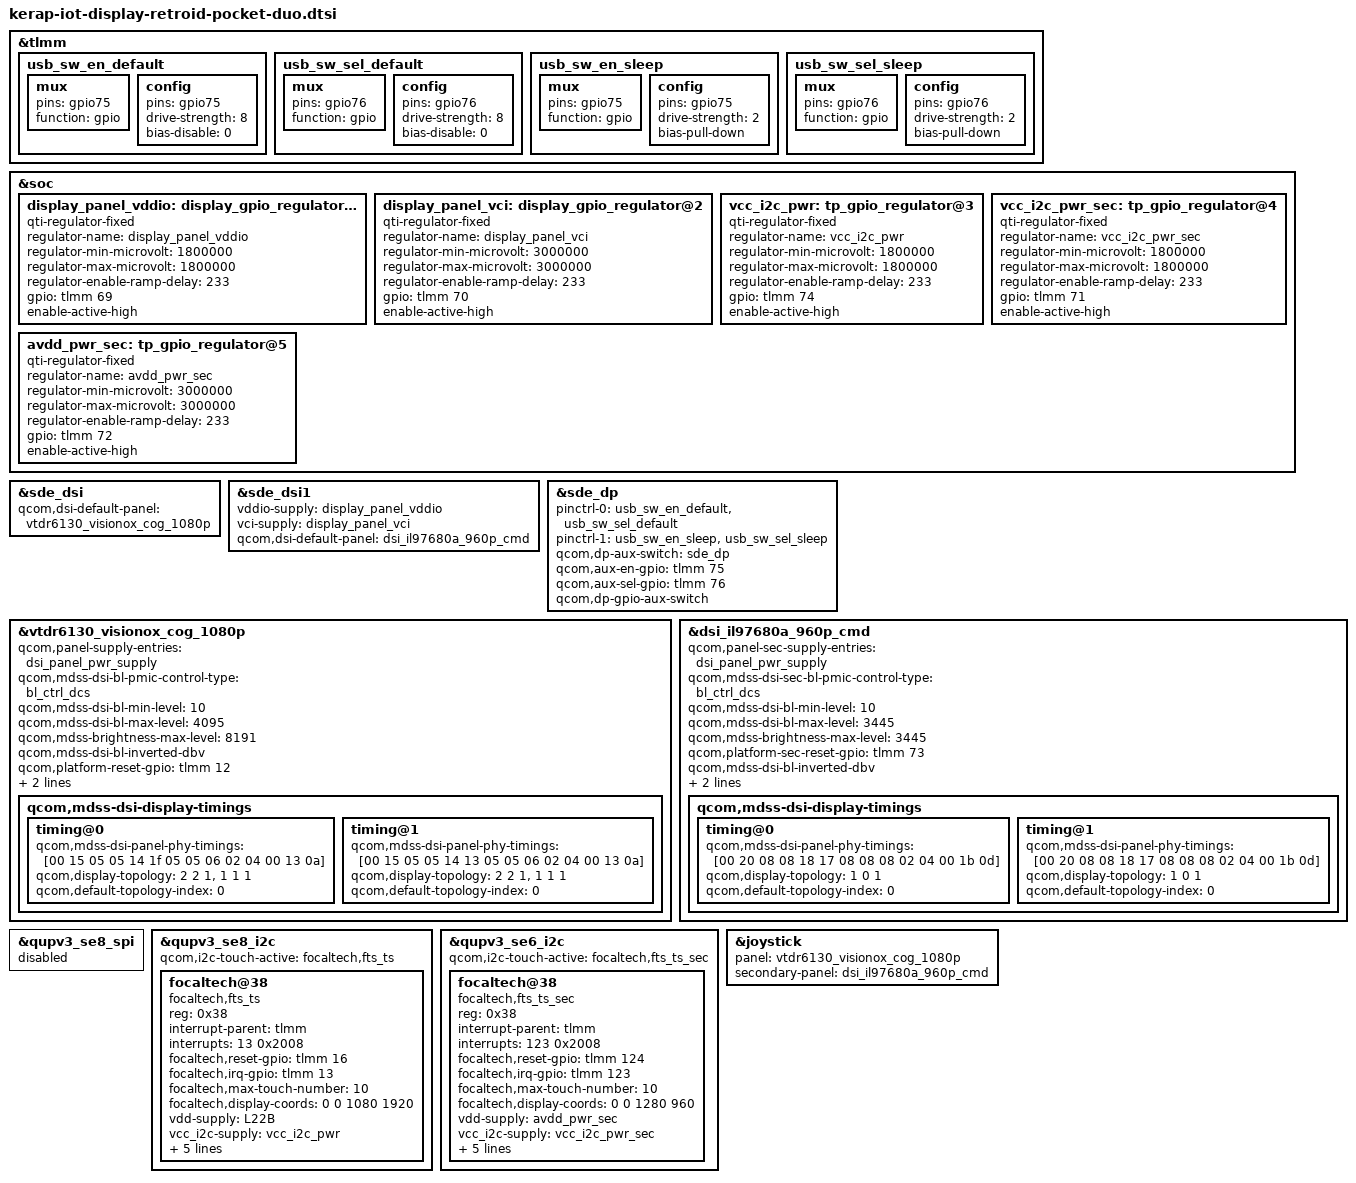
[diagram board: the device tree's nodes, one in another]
#include "../../../qcom/display/display/kera-sde.dtsi"
#include "../../../qcom/display/display/kera-sde-display-mtp.dtsi"

#include "panels/dsi-panel-il97680a-xing-960p-120hz-cmd.dtsi"
#include "panels/dsi-panel-vtdr6130-visionox-cog-1080p-cmd.dtsi"

&tlmm {
	usb_sw_en_default: usb_sw_en_default {
		mux {
			pins = "gpio75";
			function = "gpio";
		};

		config {
			pins = "gpio75";
			drive-strength = <8>;
			bias-disable = <0>;
		};
	};

	usb_sw_sel_default: usb_sw_sel_default {
		mux {
			pins = "gpio76";
			function = "gpio";
		};

		config {
			pins = "gpio76";
			drive-strength = <8>;
			bias-disable = <0>;
		};
	};

	usb_sw_en_sleep: usb_sw_en_sleep {
		mux {
			pins = "gpio75";
			function = "gpio";
		};

		config {
			pins = "gpio75";
			drive-strength = <2>;
			bias-pull-down;
		};
	};

	usb_sw_sel_sleep: usb_sw_sel_sleep {
		mux {
			pins = "gpio76";
			function = "gpio";
		};

		config {
			pins = "gpio76";
			drive-strength = <2>;
			bias-pull-down;
		};
	};
};

&soc {
	display_panel_vddio: display_gpio_regulator@1 {
		compatible = "qti-regulator-fixed";
		regulator-name = "display_panel_vddio";
		regulator-min-microvolt = <1800000>;
		regulator-max-microvolt = <1800000>;
		regulator-enable-ramp-delay = <233>;
		gpio = <&tlmm 69 0>;
		enable-active-high;
		pinctrl-names = "default";
	};

	display_panel_vci: display_gpio_regulator@2 {
		compatible = "qti-regulator-fixed";
		regulator-name = "display_panel_vci";
		regulator-min-microvolt = <3000000>;
		regulator-max-microvolt = <3000000>;
		regulator-enable-ramp-delay = <233>;
		gpio = <&tlmm 70 0>;
		enable-active-high;
		pinctrl-names = "default";
	};

	vcc_i2c_pwr: tp_gpio_regulator@3 {
		compatible = "qti-regulator-fixed";
		regulator-name = "vcc_i2c_pwr";
		regulator-min-microvolt = <1800000>;
		regulator-max-microvolt = <1800000>;
		regulator-enable-ramp-delay = <233>;
		gpio = <&tlmm 74 0>;
		enable-active-high;
		pinctrl-names = "default";
	};

	vcc_i2c_pwr_sec: tp_gpio_regulator@4 {
		compatible = "qti-regulator-fixed";
		regulator-name = "vcc_i2c_pwr_sec";
		regulator-min-microvolt = <1800000>;
		regulator-max-microvolt = <1800000>;
		regulator-enable-ramp-delay = <233>;
		gpio = <&tlmm 71 0>;
		enable-active-high;
		pinctrl-names = "default";
	};

	avdd_pwr_sec: tp_gpio_regulator@5 {
		compatible = "qti-regulator-fixed";
		regulator-name = "avdd_pwr_sec";
		regulator-min-microvolt = <3000000>;
		regulator-max-microvolt = <3000000>;
		regulator-enable-ramp-delay = <233>;
		gpio = <&tlmm 72 0>;
		enable-active-high;
		pinctrl-names = "default";
	};
};

&sde_dsi {
	qcom,dsi-default-panel = <&vtdr6130_visionox_cog_1080p>;
	status = "okay";
};

&sde_dsi1 {
	/delete-property/ vddio-supply;
	/delete-property/ vci-supply;
	vddio-supply = <&display_panel_vddio>;
	vci-supply = <&display_panel_vci>;
	qcom,dsi-default-panel = <&dsi_il97680a_960p_cmd>;
	status = "okay";
};

&sde_dp {
	pinctrl-names = "mdss_dp_active", "mdss_dp_sleep";
	pinctrl-0 = <&usb_sw_en_default &usb_sw_sel_default>;
	pinctrl-1 = <&usb_sw_en_sleep &usb_sw_sel_sleep>;
	qcom,dp-aux-switch = <&sde_dp>;
	qcom,aux-en-gpio = <&tlmm 75 0>;
	qcom,aux-sel-gpio = <&tlmm 76 0>;
	qcom,dp-gpio-aux-switch;
};

&vtdr6130_visionox_cog_1080p {
	qcom,panel-supply-entries = <&dsi_panel_pwr_supply>;
	qcom,mdss-dsi-bl-pmic-control-type = "bl_ctrl_dcs";
	qcom,mdss-dsi-bl-min-level = <10>;
	qcom,mdss-dsi-bl-max-level = <4095>;
	qcom,mdss-brightness-max-level = <8191>;
	qcom,mdss-dsi-bl-inverted-dbv;
	qcom,platform-reset-gpio = <&tlmm 12 0>;
	qcom,dsi-select-clocks = "pll_byte_clk0", "pll_dsi_clk0";

	qcom,mdss-dsi-display-timings {
		timing@0 {
			qcom,mdss-dsi-panel-phy-timings = [00 15 05 05 14 1f 05
				05 06 02 04 00 13 0a];
			qcom,display-topology = <2 2 1>, <1 1 1>;
			qcom,default-topology-index = <0>;
		};

		timing@1 {
			qcom,mdss-dsi-panel-phy-timings = [00 15 05 05 14 13 05
				05 06 02 04 00 13 0a];
			qcom,display-topology = <2 2 1>, <1 1 1>;
			qcom,default-topology-index = <0>;
		};
	};
};

&dsi_il97680a_960p_cmd {
	qcom,panel-sec-supply-entries = <&dsi_panel_pwr_supply>;
	qcom,mdss-dsi-sec-bl-pmic-control-type = "bl_ctrl_dcs";
	qcom,mdss-dsi-bl-min-level = <10>;
	qcom,mdss-dsi-bl-max-level = <3445>;
	qcom,mdss-brightness-max-level = <3445>;
	qcom,platform-sec-reset-gpio = <&tlmm 73 0>;
	qcom,mdss-dsi-bl-inverted-dbv;
	qcom,dsi-select-sec-clocks = "pll_byte_clk1", "pll_dsi_clk1";

	qcom,mdss-dsi-display-timings {
		timing@0 {
			qcom,mdss-dsi-panel-phy-timings = [00 20 08 08 18 17 08
				08 08 02 04 00 1b 0d];
			qcom,display-topology = <1 0 1>;
			qcom,default-topology-index = <0>;
		};

		timing@1 {
			qcom,mdss-dsi-panel-phy-timings = [00 20 08 08 18 17 08
				08 08 02 04 00 1b 0d];
			qcom,display-topology = <1 0 1>;
			qcom,default-topology-index = <0>;
		};
	};
};

&qupv3_se8_spi {
	status = "disabled";
};

&qupv3_se8_i2c {
	status = "okay";
	qcom,i2c-touch-active = "focaltech,fts_ts";

	focaltech@38 {
		compatible = "focaltech,fts_ts";
		reg = <0x38>;
		interrupt-parent = <&tlmm>;
		interrupts = <13 0x2008>;
		focaltech,reset-gpio = <&tlmm 16 0>;
		focaltech,irq-gpio = <&tlmm 13 0x2008>;
		focaltech,max-touch-number = <10>;
		focaltech,display-coords = <0 0 1080 1920>;
		vdd-supply = <&L22B>;
		vcc_i2c-supply = <&vcc_i2c_pwr>;
		focaltech,misconfigured-x-line-order;
		pinctrl-names = "pmx_ts_active", "pmx_ts_suspend", "pmx_ts_release";
		pinctrl-0 = <&ts_active>;
		pinctrl-1 = <&ts_int_suspend &ts_reset_suspend>;
		pinctrl-2 = <&ts_release>;
		panel = <&vtdr6130_visionox_cog_1080p>;
	};
};

&qupv3_se6_i2c {
	status = "okay";
	qcom,i2c-touch-active = "focaltech,fts_ts_sec";

	focaltech@38 {
		compatible = "focaltech,fts_ts_sec";
		reg = <0x38>;
		interrupt-parent = <&tlmm>;
		interrupts = <123 0x2008>;
		focaltech,reset-gpio = <&tlmm 124 0>;
		focaltech,irq-gpio = <&tlmm 123 0x2008>;
		focaltech,max-touch-number = <10>;
		focaltech,display-coords = <0 0 1280 960>;
		vdd-supply = <&avdd_pwr_sec>;
		vcc_i2c-supply = <&vcc_i2c_pwr_sec>;
		pinctrl-names = "pmx_sec_ts_active", "pmx_sec_ts_suspend", "pmx_sec_ts_release";
		pinctrl-0 = <&sec_ts_active>;
		pinctrl-1 = <&sec_ts_int_suspend &sec_ts_reset_suspend>;
		pinctrl-2 = <&sec_ts_release>;
		panel = <&dsi_il97680a_960p_cmd>;
	};
};

&joystick {
	panel = <&vtdr6130_visionox_cog_1080p>;
	secondary-panel = <&dsi_il97680a_960p_cmd>;
};
